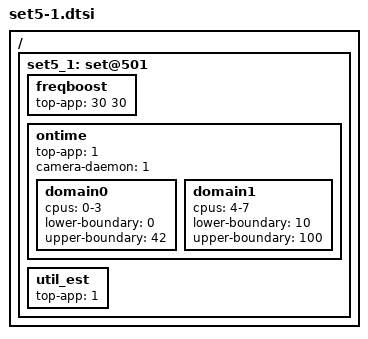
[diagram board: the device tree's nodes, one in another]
/ {
	/* camera mode - touch boost */
	set5_1: set@501 {
		/* Boosting margin applied to frequency selection */
		freqboost {
			/* LIT BIG */
			top-app		= <30 30>;
		};

		/* Ontime Migration */
		ontime {
			top-app		= <1>;
			camera-daemon 	= <1>;

			domain0 {
				cpus = "0-3";
				lower-boundary = <0>;
				upper-boundary = <42>;
			};
			domain1 {
				cpus = "4-7";
				lower-boundary = <10>;
				upper-boundary = <100>;
			};
		};

		util_est {
			top-app	= <1>;
		};
	};
};
